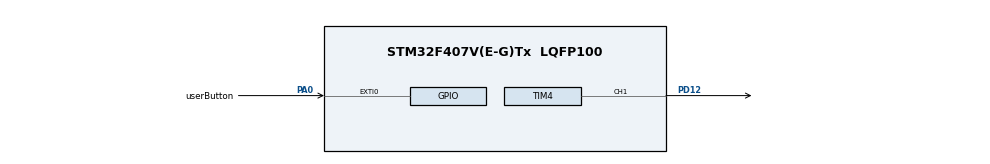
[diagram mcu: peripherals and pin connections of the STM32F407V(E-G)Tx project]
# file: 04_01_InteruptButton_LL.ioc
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Mcu.Family=STM32F4
Mcu.Name=STM32F407V(E-G)Tx
Mcu.Package=LQFP100
NVIC.EXTI0_IRQn=true\:0\:0\:false\:false\:true\:true\:true\:true
NVIC.PriorityGroup=NVIC_PRIORITYGROUP_4
PA0-WKUP.GPIO_Label=userButton
PA0-WKUP.Signal=GPXTI0
PD12.Signal=S_TIM4_CH1
PH0-OSC_IN.Mode=HSE-External-Oscillator
PH0-OSC_IN.Signal=RCC_OSC_IN
PH1-OSC_OUT.Mode=HSE-External-Oscillator
PH1-OSC_OUT.Signal=RCC_OSC_OUT
ProjectManager.HeapSize=0x200
ProjectManager.StackSize=0x400
ProjectManager.TargetToolchain=STM32CubeIDE
RCC.48MHZClocksFreq_Value=48000000
RCC.AHBFreq_Value=96000000
RCC.APB1CLKDivider=RCC_HCLK_DIV4
RCC.APB1Freq_Value=24000000
RCC.APB1TimFreq_Value=48000000
RCC.APB2CLKDivider=RCC_HCLK_DIV4
RCC.APB2Freq_Value=24000000
RCC.APB2TimFreq_Value=48000000
RCC.CortexFreq_Value=96000000
RCC.HCLKFreq_Value=96000000
RCC.HSE_VALUE=8000000
RCC.HSI_VALUE=16000000
RCC.LSE_VALUE=32768
RCC.PLLM=8
RCC.PLLSourceVirtual=RCC_PLLSOURCE_HSE
RCC.SYSCLKFreq_VALUE=96000000
RCC.SYSCLKSource=RCC_SYSCLKSOURCE_PLLCLK
RCC.VCOOutputFreq_Value=192000000
SH.S_TIM4_CH1.0=TIM4_CH1,PWM Generation1 CH1
TIM4.Channel-PWM\ Generation1\ CH1=TIM_CHANNEL_1
TIM4.Period=1000
TIM4.Prescaler=48000
board=custom

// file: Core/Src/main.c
/* USER CODE BEGIN Header */
/**
  ******************************************************************************
  * @file           : main.c
  * @brief          : Main program body
  ******************************************************************************
  * @attention
  *
  * Copyright (c) 2024 STMicroelectronics.
  * All rights reserved.
  *
  * This software is licensed under terms that can be found in the LICENSE file
  * in the root directory of this software component.
  * If no LICENSE file comes with this software, it is provided AS-IS.
  *
  ******************************************************************************
  */
/* USER CODE END Header */
#include "main.h"

void SystemClock_Config(void);
static void MX_GPIO_Init(void);
static void MX_TIM4_Init(void);

int main(void)
{

  /* MCU Configuration--------------------------------------------------------*/

  /* Reset of all peripherals, Initializes the Flash interface and the Systick. */
  LL_APB2_GRP1_EnableClock(LL_APB2_GRP1_PERIPH_SYSCFG);
  LL_APB1_GRP1_EnableClock(LL_APB1_GRP1_PERIPH_PWR);

  /* System interrupt init*/
  NVIC_SetPriorityGrouping(NVIC_PRIORITYGROUP_4);

  /* SysTick_IRQn interrupt configuration */
  NVIC_SetPriority(SysTick_IRQn, NVIC_EncodePriority(NVIC_GetPriorityGrouping(),15, 0));

  /* Configure the system clock */
  SystemClock_Config();

  /* Initialize all configured peripherals */
  MX_GPIO_Init();
  MX_TIM4_Init();
  /* USER CODE BEGIN 2 */
  LL_TIM_OC_SetCompareCH1(TIM4, 500);
  LL_TIM_CC_EnableChannel(TIM4, LL_TIM_CHANNEL_CH1);
  LL_TIM_EnableCounter(TIM4);
  LL_TIM_GenerateEvent_UPDATE(TIM4);
  /* USER CODE END 2 */

  /* Infinite loop */
  while (1)
  {

  }
}

void SystemClock_Config(void)
{
  LL_FLASH_SetLatency(LL_FLASH_LATENCY_3);
  while(LL_FLASH_GetLatency()!= LL_FLASH_LATENCY_3)
  {
  }
  LL_PWR_SetRegulVoltageScaling(LL_PWR_REGU_VOLTAGE_SCALE1);
  LL_RCC_HSE_Enable();

   /* Wait till HSE is ready */
  while(LL_RCC_HSE_IsReady() != 1)
  {

  }
  LL_RCC_PLL_ConfigDomain_SYS(LL_RCC_PLLSOURCE_HSE, LL_RCC_PLLM_DIV_8, 192, LL_RCC_PLLP_DIV_2);
  LL_RCC_PLL_Enable();

   /* Wait till PLL is ready */
  while(LL_RCC_PLL_IsReady() != 1)
  {

  }
  while (LL_PWR_IsActiveFlag_VOS() == 0)
  {
  }
  LL_RCC_SetAHBPrescaler(LL_RCC_SYSCLK_DIV_1);
  LL_RCC_SetAPB1Prescaler(LL_RCC_APB1_DIV_4);
  LL_RCC_SetAPB2Prescaler(LL_RCC_APB2_DIV_4);
  LL_RCC_SetSysClkSource(LL_RCC_SYS_CLKSOURCE_PLL);

   /* Wait till System clock is ready */
  while(LL_RCC_GetSysClkSource() != LL_RCC_SYS_CLKSOURCE_STATUS_PLL)
  {

  }
  LL_Init1msTick(96000000);
  LL_SetSystemCoreClock(96000000);
}

static void MX_TIM4_Init(void)
{

  LL_TIM_InitTypeDef TIM_InitStruct = {0};
  LL_TIM_OC_InitTypeDef TIM_OC_InitStruct = {0};

  LL_GPIO_InitTypeDef GPIO_InitStruct = {0};

  /* Peripheral clock enable */
  LL_APB1_GRP1_EnableClock(LL_APB1_GRP1_PERIPH_TIM4);

  TIM_InitStruct.Prescaler = 48000;
  TIM_InitStruct.CounterMode = LL_TIM_COUNTERMODE_UP;
  TIM_InitStruct.Autoreload = 1000;
  TIM_InitStruct.ClockDivision = LL_TIM_CLOCKDIVISION_DIV1;
  LL_TIM_Init(TIM4, &TIM_InitStruct);
  LL_TIM_DisableARRPreload(TIM4);
  LL_TIM_OC_EnablePreload(TIM4, LL_TIM_CHANNEL_CH1);
  TIM_OC_InitStruct.OCMode = LL_TIM_OCMODE_PWM1;
  TIM_OC_InitStruct.OCState = LL_TIM_OCSTATE_DISABLE;
  TIM_OC_InitStruct.OCNState = LL_TIM_OCSTATE_DISABLE;
  TIM_OC_InitStruct.CompareValue = 0;
  TIM_OC_InitStruct.OCPolarity = LL_TIM_OCPOLARITY_HIGH;
  LL_TIM_OC_Init(TIM4, LL_TIM_CHANNEL_CH1, &TIM_OC_InitStruct);
  LL_TIM_OC_DisableFast(TIM4, LL_TIM_CHANNEL_CH1);
  LL_TIM_SetTriggerOutput(TIM4, LL_TIM_TRGO_RESET);
  LL_TIM_DisableMasterSlaveMode(TIM4);
  LL_AHB1_GRP1_EnableClock(LL_AHB1_GRP1_PERIPH_GPIOD);
  /**TIM4 GPIO Configuration
  PD12   ------> TIM4_CH1
  */
  GPIO_InitStruct.Pin = LL_GPIO_PIN_12;
  GPIO_InitStruct.Mode = LL_GPIO_MODE_ALTERNATE;
  GPIO_InitStruct.Speed = LL_GPIO_SPEED_FREQ_LOW;
  GPIO_InitStruct.OutputType = LL_GPIO_OUTPUT_PUSHPULL;
  GPIO_InitStruct.Pull = LL_GPIO_PULL_NO;
  GPIO_InitStruct.Alternate = LL_GPIO_AF_2;
  LL_GPIO_Init(GPIOD, &GPIO_InitStruct);

}

static void MX_GPIO_Init(void)
{
  LL_EXTI_InitTypeDef EXTI_InitStruct = {0};

  /* GPIO Ports Clock Enable */
  LL_AHB1_GRP1_EnableClock(LL_AHB1_GRP1_PERIPH_GPIOH);
  LL_AHB1_GRP1_EnableClock(LL_AHB1_GRP1_PERIPH_GPIOA);
  LL_AHB1_GRP1_EnableClock(LL_AHB1_GRP1_PERIPH_GPIOD);

  /**/
  LL_SYSCFG_SetEXTISource(LL_SYSCFG_EXTI_PORTA, LL_SYSCFG_EXTI_LINE0);

  /**/
  EXTI_InitStruct.Line_0_31 = LL_EXTI_LINE_0;
  EXTI_InitStruct.LineCommand = ENABLE;
  EXTI_InitStruct.Mode = LL_EXTI_MODE_IT;
  EXTI_InitStruct.Trigger = LL_EXTI_TRIGGER_RISING;
  LL_EXTI_Init(&EXTI_InitStruct);

  /**/
  LL_GPIO_SetPinPull(userButton_GPIO_Port, userButton_Pin, LL_GPIO_PULL_NO);

  /**/
  LL_GPIO_SetPinMode(userButton_GPIO_Port, userButton_Pin, LL_GPIO_MODE_INPUT);

  /* EXTI interrupt init*/
  NVIC_SetPriority(EXTI0_IRQn, NVIC_EncodePriority(NVIC_GetPriorityGrouping(),0, 0));
  NVIC_EnableIRQ(EXTI0_IRQn);

}

void Error_Handler(void)
{
  __disable_irq();
  while (1)
  {
  }
}
